# ATSAMC21G17A register map
Vendor: Microchip Technology; Series: SAMC21; File version: 0
CPU: CM0+ r0p0, selectable endian, MPU, no FPU, 2 interrupt priority bits
Registers are 32-bit, read-write, reset 0x0 unless marked. A register's access mark holds for its fields unless they carry their own. Offsets are from the block's base; [hi:lo] are bit positions; {n}, {i} and the like mark numbered series.

## PAC — Peripheral Access Controller
Base 0x40000000; register names take the prefix PAC_
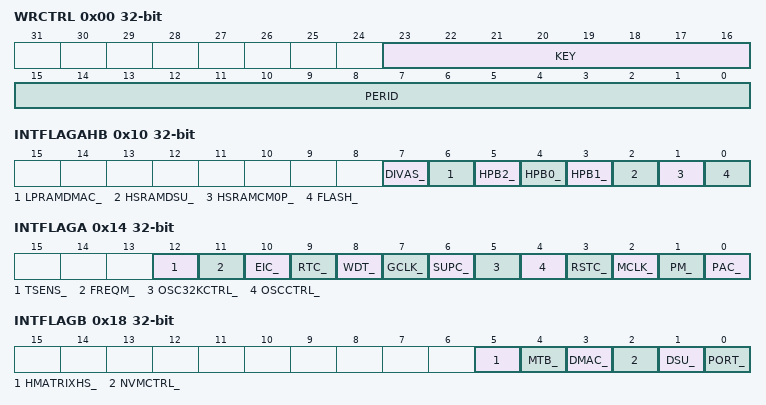
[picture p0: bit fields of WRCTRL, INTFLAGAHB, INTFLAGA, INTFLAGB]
0x00 WRCTRL — Write control
  [23:16] KEY — Peripheral access control key
    0=OFF (No action); 1=CLR (Clear protection); 2=SET (Set protection); 3=SETLCK (Set and lock protection)
  [15:0] PERID — Peripheral identifier
0x04 EVCTRL 8-bit — Event control
  [0] ERREO — Peripheral acess error event output
0x08 INTENCLR 8-bit — Interrupt enable clear
  [0] ERR — Peripheral access error interrupt disable
0x09 INTENSET 8-bit — Interrupt enable set
  [0] ERR — Peripheral access error interrupt enable
0x10 INTFLAGAHB — Bridge interrupt flag status
  [7] DIVAS_ write-1-clears, [6] LPRAMDMAC_ write-1-clears, [5] HPB2_ write-1-clears, [4] HPB0_ write-1-clears, [3] HPB1_ write-1-clears, [2] HSRAMDSU_ write-1-clears, [1] HSRAMCM0P_ write-1-clears, [0] FLASH_ write-1-clears
0x14 INTFLAGA — Peripheral interrupt flag status - Bridge A
  [12] TSENS_ write-1-clears, [11] FREQM_ write-1-clears, [10] EIC_ write-1-clears, [9] RTC_ write-1-clears, [8] WDT_ write-1-clears, [7] GCLK_ write-1-clears, [6] SUPC_ write-1-clears, [5] OSC32KCTRL_ write-1-clears, [4] OSCCTRL_ write-1-clears, [3] RSTC_ write-1-clears, [2] MCLK_ write-1-clears, [1] PM_ write-1-clears, [0] PAC_ write-1-clears
0x18 INTFLAGB — Peripheral interrupt flag status - Bridge B
  [5] HMATRIXHS_, [4] MTB_ write-1-clears, [3] DMAC_ write-1-clears, [2] NVMCTRL_ write-1-clears, [1] DSU_ write-1-clears, [0] PORT_ write-1-clears
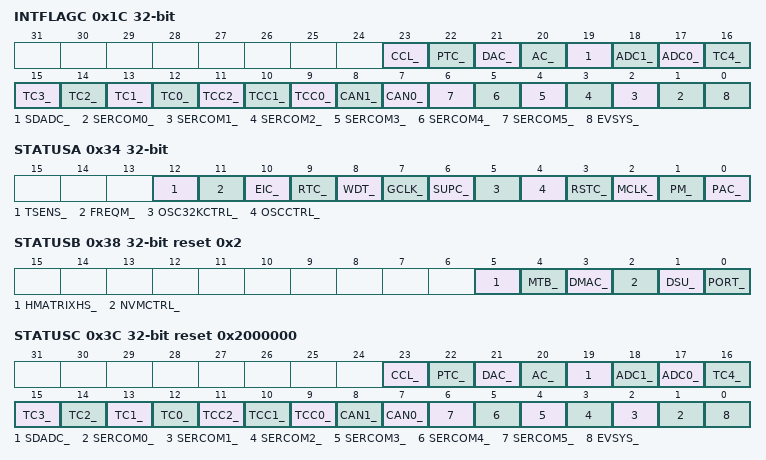
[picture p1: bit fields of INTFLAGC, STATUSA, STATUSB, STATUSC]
0x1C INTFLAGC — Peripheral interrupt flag status - Bridge C
  [23] CCL_ write-1-clears, [22] PTC_ write-1-clears, [21] DAC_ write-1-clears, [20] AC_ write-1-clears, [19] SDADC_ write-1-clears, [18] ADC1_ write-1-clears, [17] ADC0_ write-1-clears, [n+12] TC{n}_ write-1-clears (n=0..4), [11] TCC2_ write-1-clears, [10] TCC1_ write-1-clears, [9] TCC0_ write-1-clears, [8] CAN1_ write-1-clears, [7] CAN0_ write-1-clears, [n+1] SERCOM{n}_ write-1-clears (n=0..5), [0] EVSYS_ write-1-clears
0x34 STATUSA ro — Peripheral write protection status - Bridge A
  [12] TSENS_ — TSENS APB Protect Enable
  [11] FREQM_ — FREQM APB Protect Enable
  [10] EIC_ — EIC APB Protect Enable
  [9] RTC_ — RTC APB Protect Enable
  [8] WDT_ — WDT APB Protect Enable
  [7] GCLK_ — GCLK APB Protect Enable
  [6] SUPC_ — SUPC APB Protect Enable
  [5] OSC32KCTRL_ — OSC32KCTRL APB Protect Enable
  [4] OSCCTRL_ — OSCCTRL APB Protect Enable
  [3] RSTC_ — RSTC APB Protect Enable
  [2] MCLK_ — MCLK APB Protect Enable
  [1] PM_ — PM APB Protect Enable
  [0] PAC_ — PAC APB Protect Enable
0x38 STATUSB ro reset 0x2 — Peripheral write protection status - Bridge B
  [5] HMATRIXHS_ — HMATRIXHS APB Protect Enable
  [4] MTB_ — MTB APB Protect Enable
  [3] DMAC_ — DMAC APB Protect Enable
  [2] NVMCTRL_ — NVMCTRL APB Protect Enable
  [1] DSU_ — DSU APB Protect Enable
  [0] PORT_ — PORT APB Protect Enable
0x3C STATUSC ro reset 0x2000000 — Peripheral write protection status - Bridge C
  [23] CCL_ — CCL APB Protect Enable
  [22] PTC_ — PTC APB Protect Enable
  [21] DAC_ — DAC APB Protect Enable
  [20] AC_ — AC APB Protect Enable
  [19] SDADC_ — SDADC APB Protect Enable
  [18] ADC1_ — ADC1 APB Protect Enable
  [17] ADC0_ — ADC0 APB Protect Enable
  [n+12] TC{n}_ (n=0..4) — TC{n} APB Protect Enable
  [11] TCC2_ — TCC2 APB Protect Enable
  [10] TCC1_ — TCC1 APB Protect Enable
  [9] TCC0_ — TCC0 APB Protect Enable
  [8] CAN1_ — CAN1 APB Protect Enable
  [7] CAN0_ — CAN0 APB Protect Enable
  [n+1] SERCOM{n}_ (n=0..5) — SERCOM{n} APB Protect Enable
  [0] EVSYS_ — EVSYS APB Protect Enable

## PM — Power Manager
Base 0x40000400; register names take the prefix PM_
0x01 SLEEPCFG 8-bit — Sleep Configuration
  [2:0] SLEEPMODE
    0=IDLE0 (CPU clock is OFF); 1=IDLE1 (AHB clock is OFF); 2=IDLE2 (APB clock are OFF); 4=STANDBY (All Clocks are OFF)
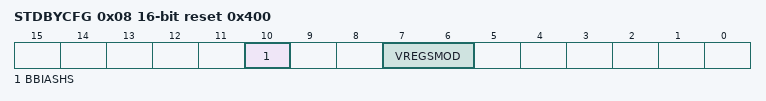
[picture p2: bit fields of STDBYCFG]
0x08 STDBYCFG 16-bit reset 0x400 — Standby Configuration
  [10] BBIASHS — Back Bias for HMCRAMCHS
  [7:6] VREGSMOD — Voltage Regulator Standby mode
    0=AUTO (Automatic mode); 1=PERFORMANCE (Performance oriented); 2=LP (Low Power oriented)
